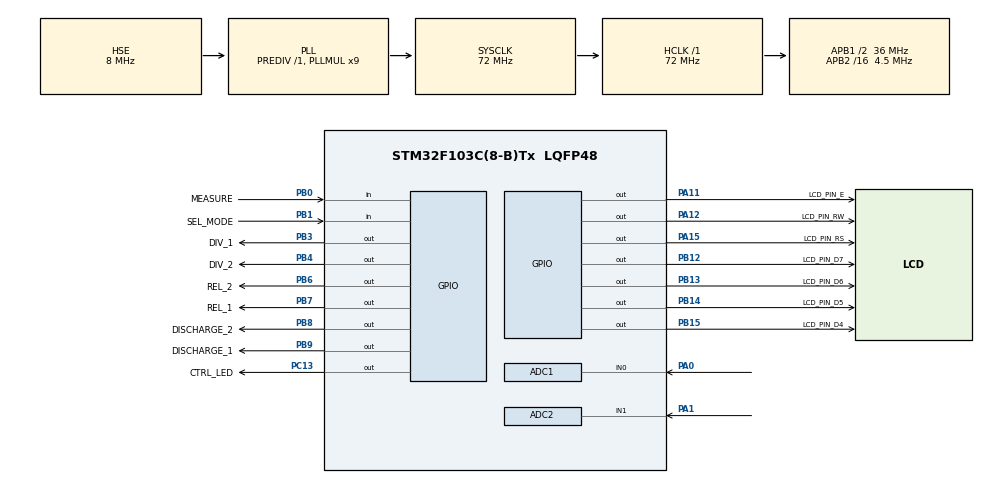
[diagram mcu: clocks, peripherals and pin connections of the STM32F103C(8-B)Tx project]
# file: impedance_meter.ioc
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ADC1.Channel-22\#ChannelRegularConversion=ADC_CHANNEL_0
ADC1.ContinuousConvMode=ENABLE
ADC1.DataAlign=ADC_DATAALIGN_RIGHT
ADC1.DiscontinuousConvMode=DISABLE
ADC1.EnableAnalogWatchDog=false
ADC1.EnableRegularConversion=ENABLE
ADC1.ExternalTrigConv=ADC_SOFTWARE_START
ADC1.InjNumberOfConversion=0
ADC1.NbrOfConversion=1
ADC1.NbrOfConversionFlag=1
ADC1.Rank-22\#ChannelRegularConversion=1
ADC1.SamplingTime-22\#ChannelRegularConversion=ADC_SAMPLETIME_1CYCLE_5
ADC1.ScanConvMode=ADC_SCAN_DISABLE
ADC1.master=1
ADC2.Channel-16\#ChannelRegularConversion=ADC_CHANNEL_1
ADC2.ContinuousConvMode=ENABLE
ADC2.DataAlign=ADC_DATAALIGN_RIGHT
ADC2.DiscontinuousConvMode=DISABLE
ADC2.EnableAnalogWatchDog=false
ADC2.EnableRegularConversion=ENABLE
ADC2.ExternalTrigConv=ADC_SOFTWARE_START
ADC2.InjNumberOfConversion=0
ADC2.NbrOfConversion=1
ADC2.NbrOfConversionFlag=1
ADC2.Rank-16\#ChannelRegularConversion=1
ADC2.SamplingTime-16\#ChannelRegularConversion=ADC_SAMPLETIME_1CYCLE_5
ADC2.ScanConvMode=ADC_SCAN_DISABLE
Mcu.Family=STM32F1
Mcu.Name=STM32F103C(8-B)Tx
Mcu.Package=LQFP48
NVIC.ADC1_2_IRQn=true\:0\:0\:false\:false\:true\:true
NVIC.PriorityGroup=NVIC_PRIORITYGROUP_4
PA0-WKUP.Signal=ADCx_IN0
PA1.Signal=ADCx_IN1
PA11.GPIO_Label=LCD_PIN_E
PA11.Signal=GPIO_Output
PA12.GPIO_Label=LCD_PIN_RW
PA12.Signal=GPIO_Output
PA15.GPIO_Label=LCD_PIN_RS
PA15.Signal=GPIO_Output
PB0.GPIO_Label=MEASURE
PB0.GPIO_PuPd=GPIO_PULLUP
PB0.Signal=GPIO_Input
PB1.GPIO_Label=SEL_MODE
PB1.GPIO_PuPd=GPIO_PULLUP
PB1.Signal=GPIO_Input
PB12.GPIO_Label=LCD_PIN_D7
PB12.Signal=GPIO_Output
PB13.GPIO_Label=LCD_PIN_D6
PB13.Signal=GPIO_Output
PB14.GPIO_Label=LCD_PIN_D5
PB14.Signal=GPIO_Output
PB15.GPIO_Label=LCD_PIN_D4
PB15.Signal=GPIO_Output
PB3.GPIO_Label=DIV_1
PB3.Signal=GPIO_Output
PB4.GPIO_Label=DIV_2
PB4.Signal=GPIO_Output
PB6.GPIO_Label=REL_2
PB6.Signal=GPIO_Output
PB7.GPIO_Label=REL_1
PB7.Signal=GPIO_Output
PB8.GPIO_Label=DISCHARGE_2
PB8.Signal=GPIO_Output
PB9.GPIO_Label=DISCHARGE_1
PB9.Signal=GPIO_Output
PC13-TAMPER-RTC.GPIO_Label=CTRL_LED
PC13-TAMPER-RTC.Signal=GPIO_Output
PD0-OSC_IN.Mode=HSE-External-Oscillator
PD0-OSC_IN.Signal=RCC_OSC_IN
PD1-OSC_OUT.Mode=HSE-External-Oscillator
PD1-OSC_OUT.Signal=RCC_OSC_OUT
ProjectManager.HeapSize=0x200
ProjectManager.StackSize=0x400
ProjectManager.TargetToolchain=Makefile
RCC.AHBFreq_Value=72000000
RCC.APB1CLKDivider=RCC_HCLK_DIV2
RCC.APB1Freq_Value=36000000
RCC.APB1TimFreq_Value=72000000
RCC.APB2CLKDivider=RCC_HCLK_DIV16
RCC.APB2Freq_Value=4500000
RCC.APB2TimFreq_Value=9000000
RCC.EnbaleCSS=true
RCC.HCLKFreq_Value=72000000
RCC.PLLMUL=RCC_PLL_MUL9
RCC.PLLSourceVirtual=RCC_PLLSOURCE_HSE
RCC.SYSCLKFreq_VALUE=72000000
RCC.SYSCLKSource=RCC_SYSCLKSOURCE_PLLCLK
RCC.USBFreq_Value=72000000
SH.ADCx_IN0.0=ADC1_IN0,IN0
SH.ADCx_IN1.0=ADC2_IN1,IN1
VP_SYS_VS_ND.Mode=No_Debug
board=impedance_meter

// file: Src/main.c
/**
  ******************************************************************************
  * @file           : main.c
  * @brief          : Main program body
  ******************************************************************************
  ** This notice applies to any and all portions of this file
  * that are not between comment pairs USER CODE BEGIN and
  * USER CODE END. Other portions of this file, whether
  * inserted by the user or by software development tools
  * are owned by their respective copyright owners.
  *
  * COPYRIGHT(c) 2018 STMicroelectronics
  *
  * Redistribution and use in source and binary forms, with or without modification,
  * are permitted provided that the following conditions are met:
  *   1. Redistributions of source code must retain the above copyright notice,
  *      this list of conditions and the following disclaimer.
  *   2. Redistributions in binary form must reproduce the above copyright notice,
  *      this list of conditions and the following disclaimer in the documentation
  *      and/or other materials provided with the distribution.
  *   3. Neither the name of STMicroelectronics nor the names of its contributors
  *      may be used to endorse or promote products derived from this software
  *      without specific prior written permission.
  *
  * THIS SOFTWARE IS PROVIDED BY THE COPYRIGHT HOLDERS AND CONTRIBUTORS "AS IS"
  * AND ANY EXPRESS OR IMPLIED WARRANTIES, INCLUDING, BUT NOT LIMITED TO, THE
  * IMPLIED WARRANTIES OF MERCHANTABILITY AND FITNESS FOR A PARTICULAR PURPOSE ARE
  * DISCLAIMED. IN NO EVENT SHALL THE COPYRIGHT HOLDER OR CONTRIBUTORS BE LIABLE
  * FOR ANY DIRECT, INDIRECT, INCIDENTAL, SPECIAL, EXEMPLARY, OR CONSEQUENTIAL
  * DAMAGES (INCLUDING, BUT NOT LIMITED TO, PROCUREMENT OF SUBSTITUTE GOODS OR
  * SERVICES; LOSS OF USE, DATA, OR PROFITS; OR BUSINESS INTERRUPTION) HOWEVER
  * CAUSED AND ON ANY THEORY OF LIABILITY, WHETHER IN CONTRACT, STRICT LIABILITY,
  * OR TORT (INCLUDING NEGLIGENCE OR OTHERWISE) ARISING IN ANY WAY OUT OF THE USE
  * OF THIS SOFTWARE, EVEN IF ADVISED OF THE POSSIBILITY OF SUCH DAMAGE.
  *
  ******************************************************************************
  */
#include "main.h"
#include "stm32f1xx_hal.h"
#include "adc.h"
#include "gpio.h"

/* USER CODE BEGIN Includes */
#include "logic.h"

/* USER CODE END Includes */

/* USER CODE BEGIN PV */
/* Private variables ---------------------------------------------------------*/

/* USER CODE END PV */

void SystemClock_Config(void);

/* USER CODE BEGIN PFP */
/* Private function prototypes -----------------------------------------------*/

/* USER CODE END PFP */

int main(void)
{

  /* MCU Configuration----------------------------------------------------------*/

  /* Reset of all peripherals, Initializes the Flash interface and the Systick. */
  HAL_Init();

  /* Configure the system clock */
  SystemClock_Config();

  /* Initialize all configured peripherals */
  MX_GPIO_Init();
  MX_ADC1_Init();
  MX_ADC2_Init();
  /* USER CODE BEGIN 2 */

  logic_init();

  /* USER CODE END 2 */

  /* Infinite loop */
  while (1)
  {

  /* USER CODE BEGIN 3 */
  logic_update();

  }
  /* USER CODE END 3 */

}

void SystemClock_Config(void)
{

  RCC_OscInitTypeDef RCC_OscInitStruct;
  RCC_ClkInitTypeDef RCC_ClkInitStruct;
  RCC_PeriphCLKInitTypeDef PeriphClkInit;

    /**Initializes the CPU, AHB and APB busses clocks
    */
  RCC_OscInitStruct.OscillatorType = RCC_OSCILLATORTYPE_HSE;
  RCC_OscInitStruct.HSEState = RCC_HSE_ON;
  RCC_OscInitStruct.HSEPredivValue = RCC_HSE_PREDIV_DIV1;
  RCC_OscInitStruct.HSIState = RCC_HSI_ON;
  RCC_OscInitStruct.PLL.PLLState = RCC_PLL_ON;
  RCC_OscInitStruct.PLL.PLLSource = RCC_PLLSOURCE_HSE;
  RCC_OscInitStruct.PLL.PLLMUL = RCC_PLL_MUL9;
  if (HAL_RCC_OscConfig(&RCC_OscInitStruct) != HAL_OK)
  {
    _Error_Handler(__FILE__, __LINE__);
  }

    /**Initializes the CPU, AHB and APB busses clocks
    */
  RCC_ClkInitStruct.ClockType = RCC_CLOCKTYPE_HCLK|RCC_CLOCKTYPE_SYSCLK
                              |RCC_CLOCKTYPE_PCLK1|RCC_CLOCKTYPE_PCLK2;
  RCC_ClkInitStruct.SYSCLKSource = RCC_SYSCLKSOURCE_PLLCLK;
  RCC_ClkInitStruct.AHBCLKDivider = RCC_SYSCLK_DIV1;
  RCC_ClkInitStruct.APB1CLKDivider = RCC_HCLK_DIV2;
  RCC_ClkInitStruct.APB2CLKDivider = RCC_HCLK_DIV16;

  if (HAL_RCC_ClockConfig(&RCC_ClkInitStruct, FLASH_LATENCY_2) != HAL_OK)
  {
    _Error_Handler(__FILE__, __LINE__);
  }

  PeriphClkInit.PeriphClockSelection = RCC_PERIPHCLK_ADC;
  PeriphClkInit.AdcClockSelection = RCC_ADCPCLK2_DIV2;
  if (HAL_RCCEx_PeriphCLKConfig(&PeriphClkInit) != HAL_OK)
  {
    _Error_Handler(__FILE__, __LINE__);
  }

    /**Enables the Clock Security System
    */
  HAL_RCC_EnableCSS();

    /**Configure the Systick interrupt time
    */
  HAL_SYSTICK_Config(HAL_RCC_GetHCLKFreq()/1000);

    /**Configure the Systick
    */
  HAL_SYSTICK_CLKSourceConfig(SYSTICK_CLKSOURCE_HCLK);

  /* SysTick_IRQn interrupt configuration */
  HAL_NVIC_SetPriority(SysTick_IRQn, 0, 0);
}

void _Error_Handler(char *file, int line)
{
  while(1)
  {
  }
}

/************************ (C) COPYRIGHT STMicroelectronics *****END OF FILE****/
